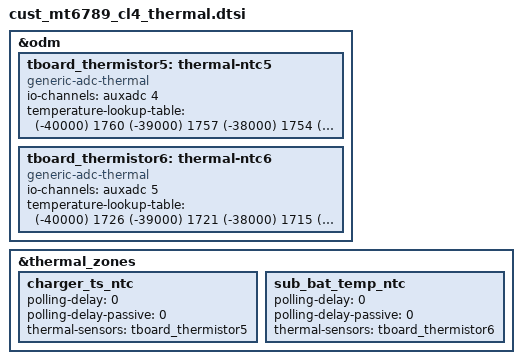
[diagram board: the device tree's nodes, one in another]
// SPDX-License-Identifier: GPL-2.0
/*
 * Copyright (c) 2024 MediaTek Inc.
 */

&odm {
        tboard_thermistor5: thermal-ntc5 {
            compatible = "generic-adc-thermal";
            #thermal-sensor-cells = <0>;
            io-channels = <&auxadc 4>;
            io-channel-names = "sensor-channel";
            temperature-lookup-table = <
                (-40000) 1760
                (-39000) 1757
                (-38000) 1754
                (-37000) 1751
                (-36000) 1747
                (-35000) 1744
                (-34000) 1740
                (-33000) 1736
                (-32000) 1731
                (-31000) 1727
                (-30000) 1722
                (-29000) 1716
                (-28000) 1711
                (-27000) 1705
                (-26000) 1699
                (-25000) 1693
                (-24000) 1686
                (-23000) 1679
                (-22000) 1672
                (-21000) 1664
                (-20000) 1656
                (-19000) 1648
                (-18000) 1639
                (-17000) 1630
                (-16000) 1620
                (-15000) 1610
                (-14000) 1599
                (-13000) 1588
                (-12000) 1577
                (-11000) 1565
                (-10000) 1553
                (-9000) 1540
                (-8000) 1527
                (-7000) 1514
                (-6000) 1500
                (-5000) 1485
                (-4000) 1470
                (-3000) 1455
                (-2000) 1439
                (-1000) 1423
                0 1406
                1000 1389
                2000 1372
                3000 1354
                4000 1335
                5000 1317
                6000 1298
                7000 1279
                8000 1259
                9000 1239
                10000 1219
                11000 1198
                12000 1178
                13000 1157
                14000 1136
                15000 1115
                16000 1093
                17000 1072
                18000 1050
                19000 1029
                20000 1007
                21000 986
                22000 964
                23000 943
                24000 921
                25000 900
                26000 879
                27000 858
                28000 837
                29000 816
                30000 796
                31000 775
                32000 755
                33000 736
                34000 716
                35000 697
                36000 678
                37000 659
                38000 641
                39000 623
                40000 605
                41000 588
                42000 571
                43000 555
                44000 538
                45000 523
                46000 507
                47000 492
                48000 477
                49000 463
                50000 449
                51000 435
                52000 422
                53000 409
                54000 396
                55000 384
                56000 372
                57000 360
                58000 349
                59000 338
                60000 327
                61000 317
                62000 307
                63000 297
                64000 288
                65000 279
                66000 270
                67000 261
                68000 253
                69000 245
                70000 237
                71000 230
                72000 222
                73000 215
                74000 209
                75000 202
                76000 196
                77000 189
                78000 183
                79000 178
                80000 172
                81000 167
                82000 161
                83000 156
                84000 151
                85000 147
                86000 142
                87000 138
                88000 133
                89000 129
                90000 125
                91000 121
                92000 118
                93000 114
                94000 111
                95000 107
                96000 104
                97000 101
                98000 98
                99000 95
                100000 92
                101000 89
                102000 87
                103000 84
                104000 81
                105000 79
                106000 77
                107000 74
                108000 72
                109000 70
                110000 68
                111000 66
                112000 64
                113000 62
                114000 61
                115000 59
                116000 57
                117000 56
                118000 54
                119000 52
                120000 51
                121000 50
                122000 48
                123000 47
                124000 46
                125000 44>;
        };
        tboard_thermistor6: thermal-ntc6 {
            compatible = "generic-adc-thermal";
            #thermal-sensor-cells = <0>;
            io-channels = <&auxadc 5>;
            io-channel-names = "sensor-channel";
            temperature-lookup-table = <
			(-40000) 1726
			(-39000) 1721
			(-38000) 1715
			(-37000) 1709
			(-36000) 1703
			(-35000) 1696
			(-34000) 1689
			(-33000) 1682
			(-32000) 1674
			(-31000) 1666
			(-30000) 1658
			(-29000) 1649
			(-28000) 1639
			(-27000) 1629
			(-26000) 1619
			(-25000) 1608
			(-24000) 1597
			(-23000) 1585
			(-22000) 1572
			(-21000) 1560
			(-20000) 1546
			(-19000) 1534
			(-18000) 1517
			(-17000) 1502
			(-16000) 1487
			(-15000) 1470
			(-14000) 1455
			(-13000) 1436
			(-12000) 1419
			(-11000) 1401
			(-10000) 1382
			(-9000) 1363
			(-8000) 1344
			(-7000) 1325
			(-6000) 1304
			(-5000) 1284
			(-4000) 1260
			(-3000) 1238
			(-2000) 1216
			(-1000) 1193
			0 1173
			1000 1149
			2000 1126
			3000 1102
			4000 1080
			5000 1056
			6000 1033
			7000 1008
			8000 985
			9000 964
			10000 939
			11000 914
			12000 891
			13000 867
			14000 845
			15000 821
			16000 799
			17000 778
			18000 755
			19000 733
			20000 714
			21000 691
			22000 670
			23000 650
			24000 623
			25000 604
			26000 586
			27000 568
			28000 550
			29000 533
			30000 516
			31000 500
			32000 483
			33000 467
			34000 452
			35000 438
			36000 423
			37000 410
			38000 395
			39000 382
			40000 369
			41000 357
			42000 346
			43000 334
			44000 322
			45000 310
			46000 300
			47000 290
			48000 280
			49000 270
			50000 261
			51000 252
			52000 243
			53000 235
			54000 227
			55000 219
			56000 211
			57000 204
			58000 197
			59000 190
			60000 183
			61000 177
			62000 171
			63000 165
			64000 160
			65000 154
			66000 149
			67000 143
			68000 139
			69000 134
			70000 130
			71000 125
			72000 121
			73000 117
			74000 113
			75000 110
			76000 106
			77000 102
			78000 99
			79000 96
			80000 93
			81000 90
			82000 86
			83000 84
			84000 81
			85000 78
			86000 76
			87000 73
			88000 71
			89000 69
			90000 67
			91000 64
			92000 62
			93000 60
			94000 59
			95000 57
			96000 55
			97000 53
			98000 52
			99000 50
			100000 48
			101000 47
			102000 46
			103000 44
			104000 43
			105000 42
			106000 40
			107000 39
			108000 38
			109000 37
			110000 36
			111000 35
			112000 34
			113000 33
			114000 32
			115000 31
			116000 30
			117000 29
			118000 28
			119000 27
			120000 27
			121000 26
			122000 25
			123000 24
			124000 24
			125000 23>;
        };
};

/*add charger_ts_ntc 、sub_bat_temp_ntc for thermal  begin(2)*/
&thermal_zones {
	charger_ts_ntc: charger_ts_ntc {
			polling-delay = <0>; /* milliseconds */
			polling-delay-passive = <0>; /* milliseconds */
			thermal-sensors = <&tboard_thermistor5>;
		};
	sub_bat_temp_ntc: sub_bat_temp_ntc {
			polling-delay = <0>; /* milliseconds */
			polling-delay-passive = <0>; /* milliseconds */
			thermal-sensors = <&tboard_thermistor6>;
		};
};
/*add charger_ts_ntc 、sub_bat_temp_ntc for thermal end(2)*/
